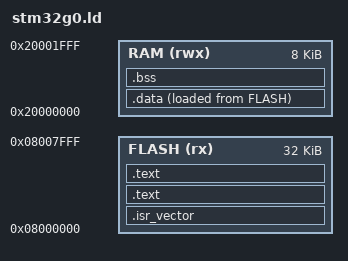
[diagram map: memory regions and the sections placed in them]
MEMORY {
    FLASH (rx) : ORIGIN = 0x08000000, LENGTH = 32K
    RAM (rwx)  : ORIGIN = 0x20000000, LENGTH = 8K
}

/* entry point of the program */
ENTRY(reset_handler)

SECTIONS {
    /* interrupt vector table, must be at the start of the flash */
    .isr_vector : {
        . = ALIGN(4);
        KEEP(*(.isr_vector))
        . = ALIGN(4);
    } > FLASH

    /* firmware code segment */
    .text : {
        . = ALIGN(4);
        *(.text)
        *(.text*)
        . = ALIGN(4);
    } > FLASH

    /* read only data segment */
    .text : {
        . = ALIGN(4);
        *(.rodata)
        *(.rodata*)
        . = ALIGN(4);
    } > FLASH

    /* initialized data segment */
    .data : {
        . = ALIGN(4);
        _sdata = .;
        *(.data)
        *(.data*)
        . = ALIGN(4);
        _edata = .;
    } > RAM AT > FLASH
    _sidata = LOADADDR(.data);

    /* zero initialized data segment */
    .bss : {
        . = ALIGN(4);
        _sbss = .;
        *(.bss)
        *(.bss*)
        . = ALIGN(4);
        _ebss = .;
    } > RAM

    /* stack pointer offset */
    _estack = ORIGIN(RAM) + LENGTH(RAM);
}

